VERSION ""

NS_ :

BS_:

BU_: XXX

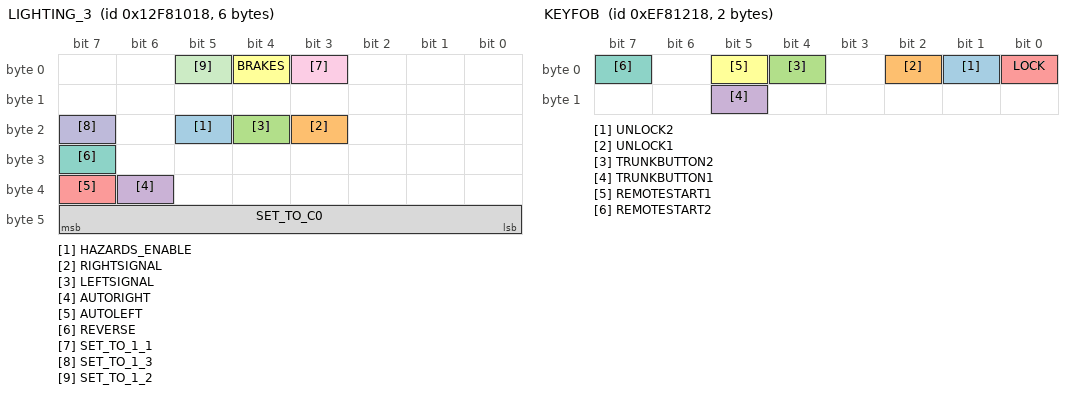
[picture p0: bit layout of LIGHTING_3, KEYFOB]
BO_ 318246936 LIGHTING_3: 6 XXX
 SG_ HAZARDS_ENABLE : 21|1@0+ (1,0) [0|1] "" XXX
 SG_ RIGHTSIGNAL : 19|1@0+ (1,0) [0|1] "" XXX
 SG_ LEFTSIGNAL : 20|1@0+ (1,0) [0|3] "" XXX
 SG_ AUTORIGHT : 38|1@0+ (1,0) [0|1] "" XXX
 SG_ AUTOLEFT : 39|1@0+ (1,0) [0|1] "" XXX
 SG_ BRAKES : 4|1@0+ (1,0) [0|1] "" XXX
 SG_ REVERSE : 31|1@0+ (1,0) [0|1] "" XXX
 SG_ SET_TO_C0 : 47|8@0+ (1,0) [0|255] "" XXX
 SG_ SET_TO_1_1 : 3|1@0+ (1,0) [0|1] "" XXX
 SG_ SET_TO_1_3 : 23|1@0+ (1,0) [0|3] "" XXX
 SG_ SET_TO_1_2 : 5|1@0+ (1,0) [0|3] "" XXX

BO_ 251138584 KEYFOB: 2 XXX
 SG_ UNLOCK2 : 1|1@0+ (1,0) [0|1] "" XXX
 SG_ UNLOCK1 : 2|1@0+ (1,0) [0|1] "" XXX
 SG_ TRUNKBUTTON2 : 4|1@0+ (1,0) [0|1] "" XXX
 SG_ TRUNKBUTTON1 : 13|1@0+ (1,0) [0|1] "" XXX
 SG_ LOCK : 0|1@0+ (1,0) [0|1] "" XXX
 SG_ REMOTESTART1 : 5|1@0+ (1,0) [0|1] "" XXX
 SG_ REMOTESTART2 : 7|1@0+ (1,0) [0|1] "" XXX

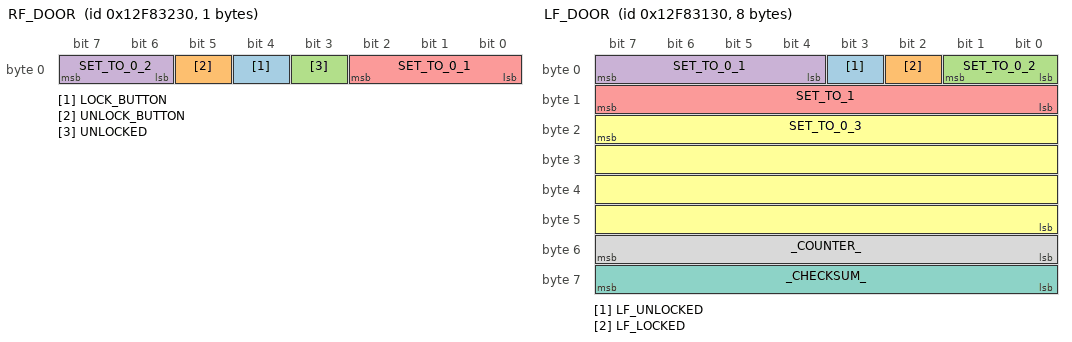
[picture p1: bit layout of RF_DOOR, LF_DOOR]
BO_ 318255664 RF_DOOR: 1 XXX
 SG_ LOCK_BUTTON : 4|1@0+ (1,0) [0|1] "" XXX
 SG_ UNLOCK_BUTTON : 5|1@0+ (1,0) [0|1] "" XXX
 SG_ UNLOCKED : 3|1@0+ (1,0) [0|1] "" XXX
 SG_ SET_TO_0_2 : 7|2@0+ (1,0) [0|3] "" XXX
 SG_ SET_TO_0_1 : 0|3@1+ (1,0) [0|7] "" XXX

BO_ 318255408 LF_DOOR: 8 XXX
 SG_ LF_UNLOCKED : 3|1@0+ (1,0) [0|1] "" XXX
 SG_ LF_LOCKED : 2|1@0+ (1,0) [0|1] "" XXX
 SG_ SET_TO_0_2 : 0|2@1+ (1,0) [0|3] "" XXX
 SG_ SET_TO_0_1 : 7|4@0+ (1,0) [0|15] "" XXX
 SG_ SET_TO_1 : 15|8@0+ (1,0) [0|255] "" XXX
 SG_ SET_TO_0_3 : 23|32@0+ (1,0) [0|4294967295] "" XXX
 SG_ _CHECKSUM_ : 56|8@1+ (1,0) [0|255] "" XXX
 SG_ _COUNTER_ : 48|8@1+ (1,0) [0|255] "" XXX

BO_ 184057368 UNK4: 3 XXX
 SG_ SET_TO_0_1 : 7|8@0+ (1,0) [0|255] "" XXX
 SG_ SET_TO_0_2 : 23|8@0+ (1,0) [0|255] "" XXX
 SG_ SET_TO_X4 : 15|8@0+ (1,0) [0|255] "" XXX

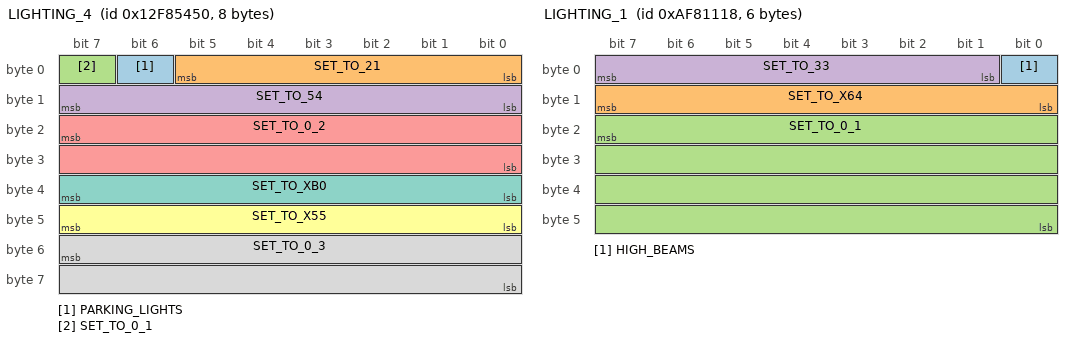
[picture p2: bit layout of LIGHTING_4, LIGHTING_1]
BO_ 318264400 LIGHTING_4: 8 XXX
 SG_ PARKING_LIGHTS : 6|1@0+ (1,0) [0|1] "" XXX
 SG_ SET_TO_21 : 5|6@0+ (1,0) [0|1] "" XXX
 SG_ SET_TO_0_1 : 7|1@0+ (1,0) [0|1] "" XXX
 SG_ SET_TO_54 : 15|8@0+ (1,0) [0|1] "" XXX
 SG_ SET_TO_0_2 : 23|16@0+ (1,0) [0|65535] "" XXX
 SG_ SET_TO_X55 : 47|8@0+ (1,0) [0|255] "" XXX
 SG_ SET_TO_XB0 : 39|8@0+ (1,0) [0|255] "" XXX
 SG_ SET_TO_0_3 : 55|16@0+ (1,0) [0|65535] "" XXX

BO_ 184029464 LIGHTING_1: 6 XXX
 SG_ HIGH_BEAMS : 0|1@0+ (1,0) [0|1] "" XXX
 SG_ SET_TO_X64 : 15|8@0+ (1,0) [0|255] "" XXX
 SG_ SET_TO_0_1 : 23|32@0+ (1,0) [0|4294967295] "" XXX
 SG_ SET_TO_33 : 7|7@0+ (1,0) [0|255] "" XXX

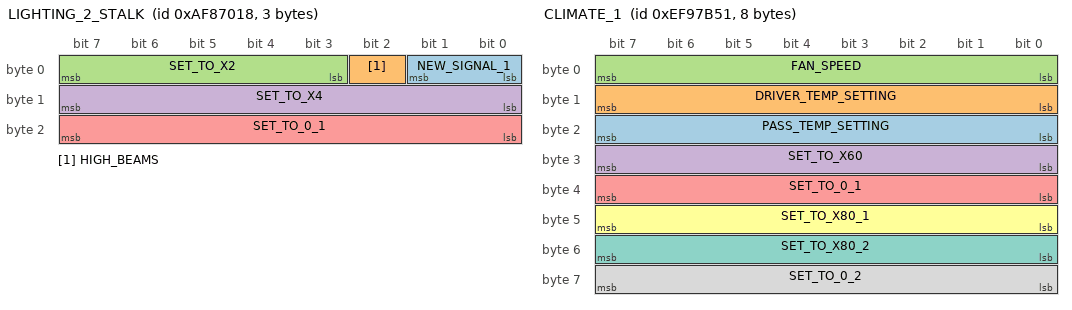
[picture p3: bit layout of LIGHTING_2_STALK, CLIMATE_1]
BO_ 184053784 LIGHTING_2_STALK: 3 XXX
 SG_ NEW_SIGNAL_1 : 0|2@1+ (1,0) [0|3] "" XXX
 SG_ HIGH_BEAMS : 2|1@0+ (1,0) [0|1] "" XXX
 SG_ SET_TO_X2 : 7|5@0+ (1,0) [0|255] "" XXX
 SG_ SET_TO_X4 : 15|8@0+ (1,0) [0|255] "" XXX
 SG_ SET_TO_0_1 : 23|8@0+ (1,0) [0|255] "" XXX

BO_ 318259736 RR_DOOR: 1 XXX
 SG_ UNLOCKED : 7|1@0+ (1,0) [0|1] "" XXX
 SG_ SET_TO_0_1 : 6|7@0+ (1,0) [0|1] "" XXX

BO_ 318288034 HEATED_SEATS: 2 XXX
 SG_ PASS_SEAT : 2|2@0+ (1,0) [0|3] "" XXX
 SG_ DRIVER_SEAT : 6|2@0+ (1,0) [0|3] "" XXX

BO_ 251231057 CLIMATE_1: 8 XXX
 SG_ PASS_TEMP_SETTING : 16|8@1+ (1,0) [0|255] "" XXX
 SG_ DRIVER_TEMP_SETTING : 8|8@1+ (1,0) [0|255] "" XXX
 SG_ FAN_SPEED : 0|8@1+ (1,0) [0|255] "" XXX
 SG_ SET_TO_X60 : 31|8@0+ (1,0) [0|1099511627775] "" XXX
 SG_ SET_TO_0_1 : 39|8@0+ (1,0) [0|255] "" XXX
 SG_ SET_TO_X80_1 : 47|8@0+ (1,0) [0|255] "" XXX
 SG_ SET_TO_X80_2 : 55|8@0+ (1,0) [0|255] "" XXX
 SG_ SET_TO_0_2 : 63|8@0+ (1,0) [0|255] "" XXX

BO_ 251142168 DOOR_LOCKS: 1 XXX
 SG_ LOCKACTION_STATUS : 7|2@0+ (1,0) [0|1] "" XXX
 SG_ SET_TO_0_ : 5|6@0+ (1,0) [0|63] "" XXX

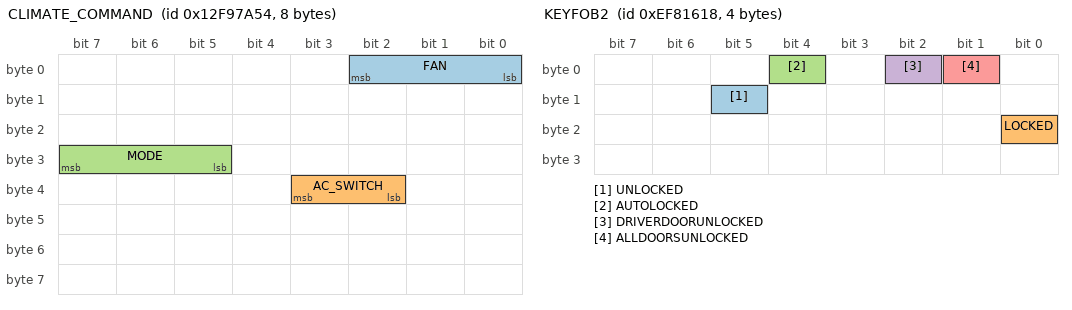
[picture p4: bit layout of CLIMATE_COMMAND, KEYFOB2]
BO_ 318339668 CLIMATE_COMMAND: 8 XXX
 SG_ FAN : 0|3@1+ (1,0) [0|7] "" XXX
 SG_ AC_SWITCH : 34|2@1+ (1,0) [0|3] "" XXX
 SG_ MODE : 31|3@0+ (1,0) [0|7] "" XXX

BO_ 251139608 KEYFOB2: 4 XXX
 SG_ UNLOCKED : 13|1@0+ (1,0) [0|1] "" XXX
 SG_ LOCKED : 16|1@0+ (1,0) [0|1] "" XXX
 SG_ AUTOLOCKED : 4|1@0+ (1,0) [0|1] "" XXX
 SG_ DRIVERDOORUNLOCKED : 2|1@0+ (1,0) [0|1] "" XXX
 SG_ ALLDOORSUNLOCKED : 1|1@0+ (1,0) [0|1] "" XXX

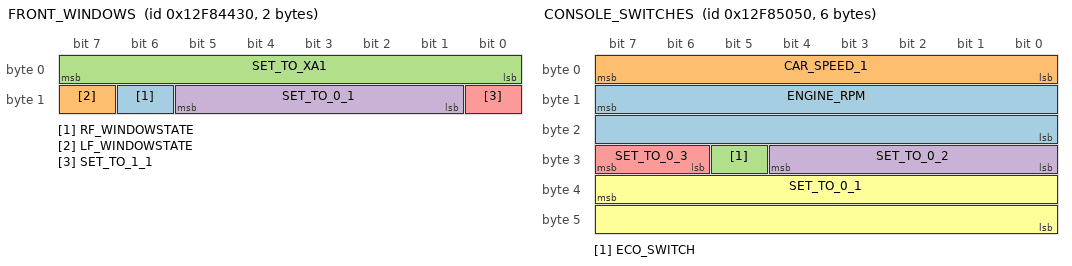
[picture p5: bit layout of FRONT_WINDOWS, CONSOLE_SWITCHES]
BO_ 318260272 FRONT_WINDOWS: 2 XXX
 SG_ RF_WINDOWSTATE : 14|1@0+ (1,0) [0|1] "" XXX
 SG_ LF_WINDOWSTATE : 15|1@0+ (1,0) [0|1] "" XXX
 SG_ SET_TO_XA1 : 7|8@0+ (1,0) [0|255] "" XXX
 SG_ SET_TO_0_1 : 13|5@0+ (1,0) [0|1] "" XXX
 SG_ SET_TO_1_1 : 8|1@0+ (1,0) [0|1] "" XXX

BO_ 318263376 CONSOLE_SWITCHES: 6 XXX
 SG_ ENGINE_RPM : 15|16@0+ (1,0) [0|65535] "" XXX
 SG_ CAR_SPEED_1 : 7|8@0+ (1,0) [0|255] "" XXX
 SG_ ECO_SWITCH : 29|1@0+ (1,0) [0|1] "" XXX
 SG_ SET_TO_0_2 : 28|5@0+ (1,0) [0|31] "" XXX
 SG_ SET_TO_0_3 : 31|2@0+ (1,0) [0|3] "" XXX
 SG_ SET_TO_0_1 : 39|16@0+ (1,0) [0|255] "" XXX

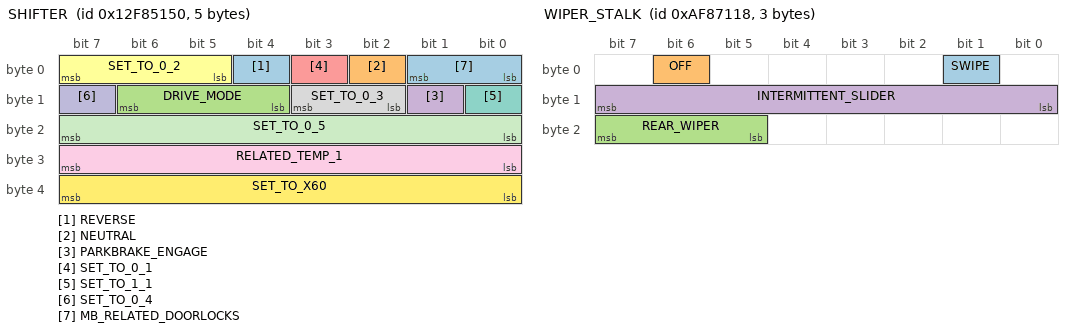
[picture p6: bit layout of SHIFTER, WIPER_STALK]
BO_ 318263632 SHIFTER: 5 XXX
 SG_ REVERSE : 4|1@0+ (1,0) [0|1] "" XXX
 SG_ NEUTRAL : 2|1@0+ (1,0) [0|1] "" XXX
 SG_ DRIVE_MODE : 14|3@0+ (1,0) [0|7] "" XXX
 SG_ PARKBRAKE_ENGAGE : 9|1@0+ (1,0) [0|1] "" XXX
 SG_ SET_TO_0_1 : 3|1@0+ (1,0) [0|1] "" XXX
 SG_ SET_TO_0_2 : 7|3@0+ (1,0) [0|7] "" XXX
 SG_ SET_TO_1_1 : 8|1@0+ (1,0) [0|1] "" XXX
 SG_ SET_TO_0_3 : 10|2@1+ (1,0) [0|3] "" XXX
 SG_ RELATED_TEMP_1 : 31|8@0+ (1,0) [0|255] "" XXX
 SG_ SET_TO_0_4 : 15|1@0+ (1,0) [0|1] "" XXX
 SG_ SET_TO_0_5 : 23|8@0+ (1,0) [0|16777215] "" XXX
 SG_ SET_TO_X60 : 39|8@0+ (1,0) [0|255] "" XXX
 SG_ MB_RELATED_DOORLOCKS : 1|2@0+ (1,0) [0|1] "" XXX

BO_ 318337360 STEERING_1: 3 XXX
 SG_ STEER_ANGLE : 15|16@0- (1,0) [0|255] "" XXX
 SG_ SET_TO_XE0 : 7|8@0+ (1,0) [0|255] "" XXX

BO_ 184054040 WIPER_STALK: 3 XXX
 SG_ SWIPE : 1|1@0+ (1,0) [0|1] "" XXX
 SG_ OFF : 6|1@0+ (1,0) [0|1] "" XXX
 SG_ REAR_WIPER : 23|3@0+ (1,0) [0|7] "" XXX
 SG_ INTERMITTENT_SLIDER : 15|8@0+ (1,0) [0|255] "" XXX

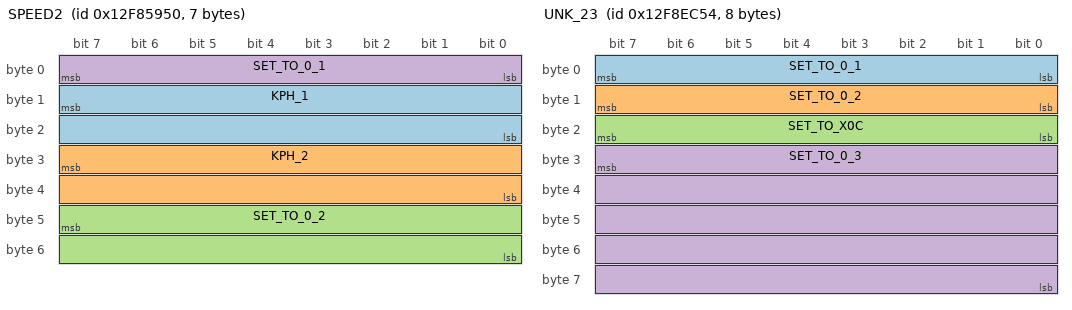
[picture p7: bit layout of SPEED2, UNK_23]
BO_ 318265680 SPEED2: 7 XXX
 SG_ KPH_1 : 15|16@0+ (0.01,0) [0|65535] "" XXX
 SG_ KPH_2 : 31|16@0+ (0.01,0) [0|65535] "" XXX
 SG_ SET_TO_0_2 : 47|16@0+ (1,0) [0|65535] "" XXX
 SG_ SET_TO_0_1 : 7|8@0+ (1,0) [0|255] "" XXX

BO_ 318303316 UNK_23: 8 XXX
 SG_ SET_TO_0_1 : 7|8@0+ (1,0) [0|255] "" XXX
 SG_ SET_TO_0_2 : 15|8@0+ (1,0) [0|255] "" XXX
 SG_ SET_TO_X0C : 23|8@0+ (1,0) [0|255] "" XXX
 SG_ SET_TO_0_3 : 31|40@0+ (1,0) [0|1099511627775] "" XXX

BO_ 318259480 LR_DOOR: 1 XXX
 SG_ UNLOCKED : 7|1@0+ (1,0) [0|1] "" XXX
 SG_ SET_TO_0_1 : 6|7@0+ (1,0) [0|1] "" XXX

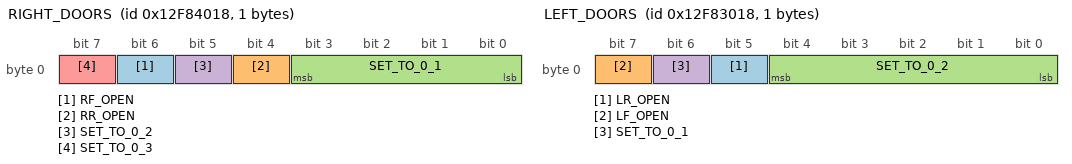
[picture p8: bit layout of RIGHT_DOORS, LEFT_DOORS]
BO_ 318259224 RIGHT_DOORS: 1 XXX
 SG_ RF_OPEN : 6|1@0+ (1,0) [0|1] "" XXX
 SG_ RR_OPEN : 4|1@0+ (1,0) [0|1] "" XXX
 SG_ SET_TO_0_1 : 3|4@0+ (1,0) [0|1] "" XXX
 SG_ SET_TO_0_2 : 5|1@0+ (1,0) [0|1] "" XXX
 SG_ SET_TO_0_3 : 7|1@0+ (1,0) [0|1] "" XXX

BO_ 318255128 LEFT_DOORS: 1 XXX
 SG_ LR_OPEN : 5|1@0+ (1,0) [0|1] "" XXX
 SG_ LF_OPEN : 7|1@0+ (1,0) [0|1] "" XXX
 SG_ SET_TO_0_2 : 4|5@0+ (1,0) [0|31] "" XXX
 SG_ SET_TO_0_1 : 6|1@0+ (1,0) [0|1] "" XXX

BO_ 318275608 TRUNK_1: 1 XXX
 SG_ RELEASE_BUTTON : 7|1@0+ (1,0) [0|1] "" XXX
 SG_ SET_TO_0_1 : 6|7@0+ (1,0) [0|127] "" XXX

BO_ 318259992 TRUNK_2: 1 XXX
 SG_ TRUNK_OPEN : 7|1@0+ (1,0) [0|1] "" XXX
 SG_ SET_TO_0_1 : 6|7@0+ (1,0) [0|1] "" XXX

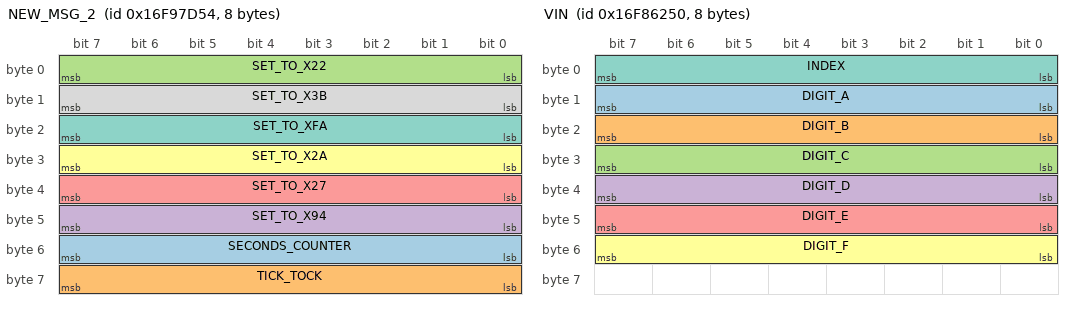
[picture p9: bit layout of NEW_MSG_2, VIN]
BO_ 385449300 NEW_MSG_2: 8 XXX
 SG_ SECONDS_COUNTER : 55|8@0+ (1,0) [0|255] "" XXX
 SG_ TICK_TOCK : 56|8@1+ (1,0) [0|255] "" XXX
 SG_ SET_TO_X22 : 7|8@0+ (1,0) [0|65535] "" XXX
 SG_ SET_TO_X94 : 47|8@0+ (1,0) [0|255] "" XXX
 SG_ SET_TO_X27 : 39|8@0+ (1,0) [0|1] "" XXX
 SG_ SET_TO_X2A : 31|8@0+ (1,0) [0|255] "" XXX
 SG_ SET_TO_XFA : 23|8@0+ (1,0) [0|1] "" XXX
 SG_ SET_TO_X3B : 15|8@0+ (1,0) [0|255] "" XXX

BO_ 385376848 VIN: 8 XXX
 SG_ DIGIT_A : 15|8@0+ (1,0) [0|255] "" XXX
 SG_ DIGIT_B : 23|8@0+ (1,0) [0|255] "" XXX
 SG_ DIGIT_C : 31|8@0+ (1,0) [0|255] "" XXX
 SG_ DIGIT_D : 39|8@0+ (1,0) [0|255] "" XXX
 SG_ DIGIT_E : 47|8@0+ (1,0) [0|255] "" XXX
 SG_ DIGIT_F : 55|8@0+ (1,0) [0|255] "" XXX
 SG_ INDEX : 7|8@0+ (1,0) [0|255] "" XXX

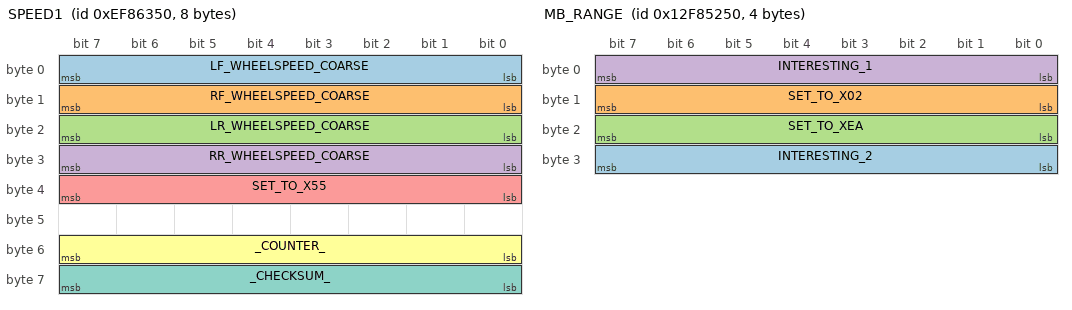
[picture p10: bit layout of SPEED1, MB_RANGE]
BO_ 251159376 SPEED1: 8 XXX
 SG_ LF_WHEELSPEED_COARSE : 0|8@1+ (1,0) [0|255] "" XXX
 SG_ RF_WHEELSPEED_COARSE : 8|8@1+ (1,0) [0|255] "" XXX
 SG_ LR_WHEELSPEED_COARSE : 16|8@1+ (1,0) [0|255] "" XXX
 SG_ RR_WHEELSPEED_COARSE : 24|8@1+ (1,0) [0|255] "" XXX
 SG_ SET_TO_X55 : 39|8@0+ (1,0) [0|255] "" XXX
 SG_ _COUNTER_ : 55|8@0+ (1,0) [0|255] "" XXX
 SG_ _CHECKSUM_ : 63|8@0+ (1,0) [0|255] "" XXX

BO_ 251234897 VEH_DYN_1: 2 XXX
 SG_ unk_maybe_fuel_usage : 7|16@0- (1,0) [0|255] "" XXX

BO_ 318338128 STEERING_2: 2 XXX
 SG_ RELATED_STEER_ANGLE : 7|8@0+ (1,0) [0|255] "" XXX
 SG_ MAYBE_STEER_DIRECTION : 15|8@0+ (1,0) [0|255] "" XXX

BO_ 318292308 NEW_MSG_5: 8 XXX
 SG_ NEW_SIGNAL_1 : 7|24@0+ (1,0) [0|65535] "" XXX
 SG_ NEW_SIGNAL_3 : 31|24@0+ (1,0) [0|65535] "" XXX
 SG_ NEW_SIGNAL_4 : 55|16@0+ (1,0) [0|65535] "" XXX

BO_ 318263888 MB_RANGE: 4 XXX
 SG_ INTERESTING_2 : 31|8@0+ (1,0) [0|255] "" XXX
 SG_ SET_TO_X02 : 15|8@0+ (1,0) [0|255] "" XXX
 SG_ SET_TO_XEA : 23|8@0+ (1,0) [0|255] "" XXX
 SG_ INTERESTING_1 : 7|8@0+ (1,0) [0|255] "" XXX

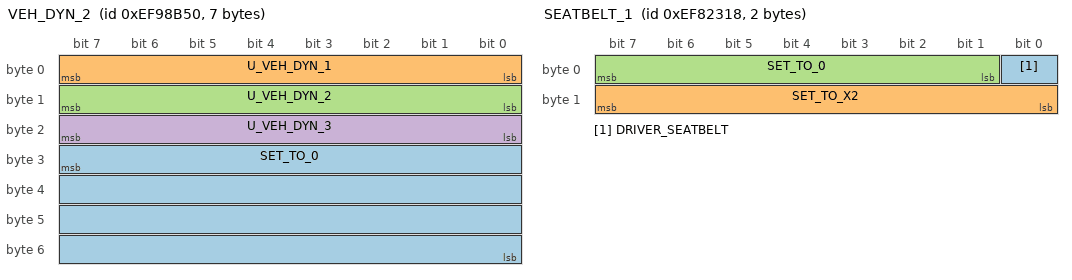
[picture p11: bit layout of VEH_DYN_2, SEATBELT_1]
BO_ 251235152 VEH_DYN_2: 7 XXX
 SG_ SET_TO_0 : 31|32@0+ (1,0) [0|4294967295] "" XXX
 SG_ U_VEH_DYN_1 : 7|8@0+ (1,0) [0|255] "" XXX
 SG_ U_VEH_DYN_2 : 15|8@0+ (1,0) [0|255] "" XXX
 SG_ U_VEH_DYN_3 : 23|8@0+ (1,0) [0|255] "" XXX

BO_ 318333008 UNK_1: 7 XXX
 SG_ SET_TO_0_1 : 7|32@0+ (1,0) [0|255] "" XXX
 SG_ SET_TO_0_X09 : 47|8@0+ (1,0) [0|255] "" XXX
 SG_ SET_TO_0_X40 : 39|8@0+ (1,0) [0|255] "" XXX
 SG_ SET_TO_0_2 : 55|8@0+ (1,0) [0|255] "" XXX

BO_ 318343249 UNK_2: 3 XXX
 SG_ SET_TO_X40 : 7|8@0+ (1,0) [0|255] "" XXX
 SG_ SET_TO_0_1 : 15|8@0+ (1,0) [0|255] "" XXX
 SG_ SET_TO_0_2 : 23|8@0+ (1,0) [0|255] "" XXX

BO_ 184057168 UNK_3: 2 XXX
 SG_ SET_TO_0_1 : 7|8@0+ (1,0) [0|255] "" XXX
 SG_ SET_TO_0_2 : 15|8@0+ (1,0) [0|255] "" XXX

BO_ 184121680 UNK_5: 1 XXX
 SG_ SET_TO_0 : 7|8@0+ (1,0) [0|255] "" XXX

BO_ 251139096 UNK_6: 1 XXX
 SG_ SET_TO_0 : 7|8@0+ (1,0) [0|255] "" XXX

BO_ 251139352 UNK_7: 1 XXX
 SG_ SET_TO_2 : 7|8@0+ (1,0) [0|255] "" XXX

BO_ 251142936 SEATBELT_1: 2 XXX
 SG_ DRIVER_SEATBELT : 0|1@0+ (1,0) [0|1] "" XXX
 SG_ SET_TO_X2 : 15|8@0+ (1,0) [0|255] "" XXX
 SG_ SET_TO_0 : 7|7@0+ (1,0) [0|255] "" XXX

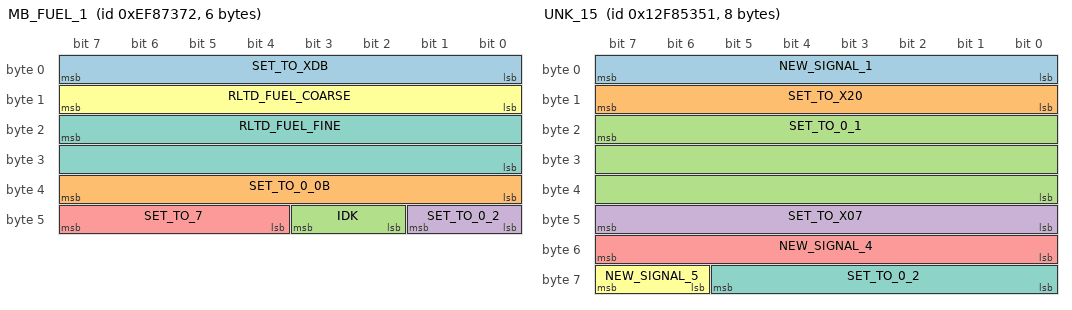
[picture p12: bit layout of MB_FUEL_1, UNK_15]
BO_ 251163506 MB_FUEL_1: 6 XXX
 SG_ SET_TO_XDB : 7|8@0+ (1,0) [0|255] "" XXX
 SG_ SET_TO_0_0B : 39|8@0+ (1,0) [0|255] "" XXX
 SG_ IDK : 42|2@1+ (1,0) [0|3] "" XXX
 SG_ SET_TO_0_2 : 40|2@1+ (1,0) [0|3] "" XXX
 SG_ SET_TO_7 : 47|4@0+ (1,0) [0|255] "" XXX
 SG_ RLTD_FUEL_COARSE : 15|8@0+ (1,0) [0|255] "" XXX
 SG_ RLTD_FUEL_FINE : 23|16@0+ (1,0) [0|1] "" XXX

BO_ 251167000 UNK_9: 1 XXX
 SG_ SET_TO_0 : 7|8@0+ (1,0) [0|255] "" XXX

BO_ 251167512 UNK_10: 8 XXX
 SG_ SET_TO_0_1 : 7|24@0+ (1,0) [0|8388607] "" XXX
 SG_ SET_TO_X09 : 31|8@0+ (1,0) [0|255] "" XXX
 SG_ SET_TO_0_2 : 39|32@0+ (1,0) [0|4294967295] "" XXX

BO_ 251171864 UNK_11: 3 XXX
 SG_ NEW_SIGNAL_1 : 7|8@0+ (1,0) [0|255] "" XXX
 SG_ NEW_SIGNAL_2 : 15|8@0+ (1,0) [0|255] "" XXX
 SG_ NEW_SIGNAL_3 : 23|8@0+ (1,0) [0|255] "" XXX

BO_ 318254104 UNK_12: 1 XXX
 SG_ SET_TO_X20 : 7|8@0+ (1,0) [0|255] "" XXX

BO_ 318256152 UNK_13: 1 XXX
 SG_ SET_TO_X20 : 7|8@0+ (1,0) [0|255] "" XXX

BO_ 318261784 UNK_14: 1 XXX
 SG_ SET_TO_0_1 : 7|8@0+ (1,0) [0|255] "" XXX

BO_ 318264145 UNK_15: 8 XXX
 SG_ NEW_SIGNAL_1 : 7|8@0+ (1,0) [0|65535] "" XXX
 SG_ SET_TO_X20 : 15|8@0+ (1,0) [0|1] "" XXX
 SG_ SET_TO_0_1 : 23|24@0+ (1,0) [0|1] "" XXX
 SG_ SET_TO_X07 : 47|8@0+ (1,0) [0|1] "" XXX
 SG_ NEW_SIGNAL_4 : 55|8@0+ (1,0) [0|1] "" XXX
 SG_ NEW_SIGNAL_5 : 62|2@1+ (1,0) [0|1] "" XXX
 SG_ SET_TO_0_2 : 61|6@0+ (1,0) [0|63] "" XXX

BO_ 318266448 UNK_16: 6 XXX
 SG_ SET_TO_0_1 : 7|48@0+ (1,0) [0|255] "" XXX

BO_ 318267728 UNK_17: 8 XXX
 SG_ SET_TO_0_1 : 7|24@0+ (1,0) [0|1] "" XXX
 SG_ SET_TO_X40 : 31|8@0+ (1,0) [0|255] "" XXX
 SG_ SET_TO_0_2 : 39|32@0+ (1,0) [0|1] "" XXX

BO_ 318273560 UNK_18: 1 XXX
 SG_ SET_TO_0_1 : 7|8@0+ (1,0) [0|255] "" XXX

BO_ 318279704 UNK_19: 4 XXX
 SG_ SET_TO_0_1 : 7|8@0+ (1,0) [0|255] "" XXX
 SG_ SET_TO_X01 : 15|8@0+ (1,0) [0|255] "" XXX
 SG_ SET_TO_0_2 : 23|8@0+ (1,0) [0|255] "" XXX
 SG_ SET_TO_0_3 : 31|8@0+ (1,0) [0|255] "" XXX

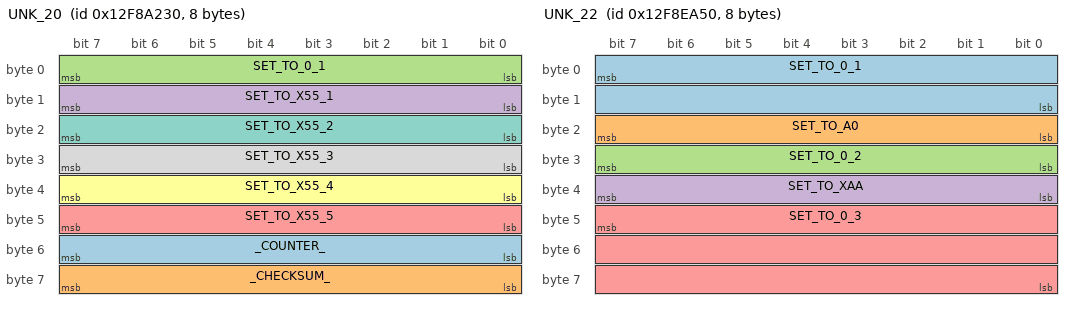
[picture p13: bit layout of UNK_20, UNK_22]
BO_ 318284336 UNK_20: 8 XXX
 SG_ _COUNTER_ : 55|8@0+ (1,0) [0|255] "" XXX
 SG_ _CHECKSUM_ : 63|8@0+ (1,0) [0|1] "" XXX
 SG_ SET_TO_0_1 : 7|8@0+ (1,0) [0|255] "" XXX
 SG_ SET_TO_X55_1 : 15|8@0+ (1,0) [0|255] "" XXX
 SG_ SET_TO_X55_5 : 47|8@0+ (1,0) [0|255] "" XXX
 SG_ SET_TO_X55_4 : 39|8@0+ (1,0) [0|255] "" XXX
 SG_ SET_TO_X55_2 : 23|8@0+ (1,0) [0|255] "" XXX
 SG_ SET_TO_X55_3 : 31|8@0+ (1,0) [0|255] "" XXX

BO_ 318288209 UNK_21: 4 XXX
 SG_ SET_TO_0_1 : 7|32@0+ (1,0) [0|4294967295] "" XXX

BO_ 318302800 UNK_22: 8 XXX
 SG_ SET_TO_0_1 : 7|16@0+ (1,0) [0|65535] "" XXX
 SG_ SET_TO_A0 : 23|8@0+ (1,0) [0|255] "" XXX
 SG_ SET_TO_0_2 : 31|8@0+ (1,0) [0|255] "" XXX
 SG_ SET_TO_XAA : 39|8@0+ (1,0) [0|255] "" XXX
 SG_ SET_TO_0_3 : 47|24@0+ (1,0) [0|16777215] "" XXX

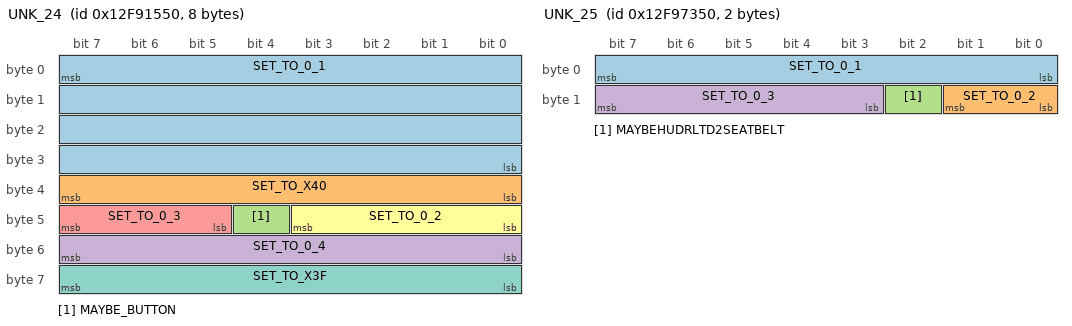
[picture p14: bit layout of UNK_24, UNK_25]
BO_ 318313808 UNK_24: 8 XXX
 SG_ SET_TO_0_1 : 7|32@0+ (1,0) [0|4294967295] "" XXX
 SG_ SET_TO_X40 : 39|8@0+ (1,0) [0|255] "" XXX
 SG_ MAYBE_BUTTON : 44|1@0+ (1,0) [0|1] "" XXX
 SG_ SET_TO_0_4 : 55|8@0+ (1,0) [0|255] "" XXX
 SG_ SET_TO_0_3 : 47|3@0+ (1,0) [0|65535] "" XXX
 SG_ SET_TO_0_2 : 40|4@1+ (1,0) [0|15] "" XXX
 SG_ SET_TO_X3F : 63|8@0+ (1,0) [0|255] "" XXX

BO_ 318337872 UNK_25: 2 XXX
 SG_ SET_TO_0_1 : 7|8@0+ (1,0) [0|255] "" XXX
 SG_ SET_TO_0_2 : 9|2@0+ (1,0) [0|1] "" XXX
 SG_ MAYBEHUDRLTD2SEATBELT : 10|1@0+ (1,0) [0|1] "" XXX
 SG_ SET_TO_0_3 : 15|5@0+ (1,0) [0|255] "" XXX

BO_ 318361624 UNK_26: 1 XXX
 SG_ SET_TO_0_1 : 7|8@0+ (1,0) [0|255] "" XXX

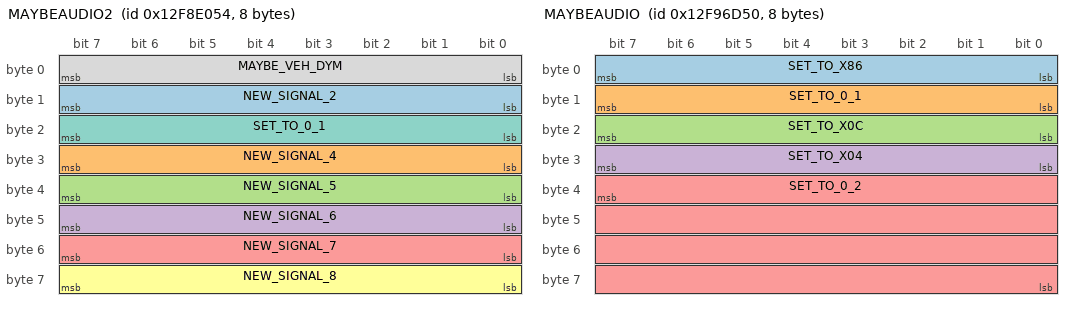
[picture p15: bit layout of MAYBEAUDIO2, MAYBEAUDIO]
BO_ 318300244 MAYBEAUDIO2: 8 XXX
 SG_ NEW_SIGNAL_2 : 15|8@0+ (1,0) [0|255] "" XXX
 SG_ NEW_SIGNAL_4 : 31|8@0+ (1,0) [0|255] "" XXX
 SG_ NEW_SIGNAL_5 : 39|8@0+ (1,0) [0|255] "" XXX
 SG_ NEW_SIGNAL_6 : 47|8@0+ (1,0) [0|255] "" XXX
 SG_ NEW_SIGNAL_7 : 55|8@0+ (1,0) [0|255] "" XXX
 SG_ NEW_SIGNAL_8 : 63|8@0+ (1,0) [0|255] "" XXX
 SG_ SET_TO_0_1 : 23|8@0+ (1,0) [0|255] "" XXX
 SG_ MAYBE_VEH_DYM : 7|8@0+ (1,0) [0|255] "" XXX

BO_ 318336336 MAYBEAUDIO: 8 XXX
 SG_ SET_TO_X86 : 7|8@0+ (1,0) [0|255] "" XXX
 SG_ SET_TO_0_1 : 15|8@0+ (1,0) [0|255] "" XXX
 SG_ SET_TO_X0C : 23|8@0+ (1,0) [0|255] "" XXX
 SG_ SET_TO_X04 : 31|8@0+ (1,0) [0|255] "" XXX
 SG_ SET_TO_0_2 : 39|32@0+ (1,0) [0|4294967295] "" XXX

BO_ 318251544 UNK_27: 1 XXX
 SG_ SET_TO_X80 : 7|8@0+ (1,0) [0|255] "" XXX

BO_ 318332752 MB_SECURITY_2: 8 XXX

BO_ 318336596 MB_SECURITY_3: 8 XXX

BO_ 318340176 MB_SECURITY_4: 1 XXX

BO_ 317390673 MB_SECURITY_5: 2 XXX

BO_ 317390676 MB_SECURITY_6: 8 XXX

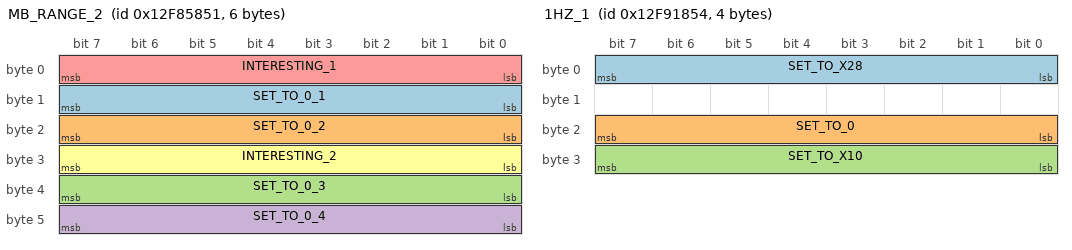
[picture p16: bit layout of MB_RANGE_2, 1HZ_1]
BO_ 318265425 MB_RANGE_2: 6 XXX
 SG_ SET_TO_0_1 : 15|8@0+ (1,0) [0|255] "" XXX
 SG_ SET_TO_0_2 : 23|8@0+ (1,0) [0|255] "" XXX
 SG_ SET_TO_0_3 : 39|8@0+ (1,0) [0|255] "" XXX
 SG_ SET_TO_0_4 : 47|8@0+ (1,0) [0|255] "" XXX
 SG_ INTERESTING_1 : 7|8@0+ (1,0) [0|255] "" XXX
 SG_ INTERESTING_2 : 31|8@0+ (1,0) [0|255] "" XXX

BO_ 318302292 UNK_EVENT_1: 4 XXX

BO_ 318302548 UNK_EVENT_2: 8 XXX

BO_ 318314580 1HZ_1: 4 XXX
 SG_ SET_TO_X28 : 7|8@0+ (1,0) [0|255] "" XXX
 SG_ SET_TO_0 : 23|8@0+ (1,0) [0|255] "" XXX
 SG_ SET_TO_X10 : 31|8@0+ (1,0) [0|255] "" XXX

BO_ 318329172 1HZ_2: 8 XXX

BO_ 318333264 3SEC_1: 7 XXX

BO_ 318333520 UNK_EVENT_3: 8 XXX

BO_ 318334800 UNK_EVENT_4: 8 XXX

BO_ 318335824 UNK_EVENT_5: 8 XXX

BO_ 318338640 1HZ_3: 8 XXX

BO_ 318357584 1HZ_4: 8 XXX

BO_ 318357840 1HZ_5: 8 XXX

BO_ 384913492 ACC_EVENT_1: 2 XXX
 SG_ NEW_SIGNAL_1 : 7|8@0+ (1,0) [0|255] "" XXX
 SG_ NEW_SIGNAL_2 : 15|8@0+ (1,0) [0|255] "" XXX

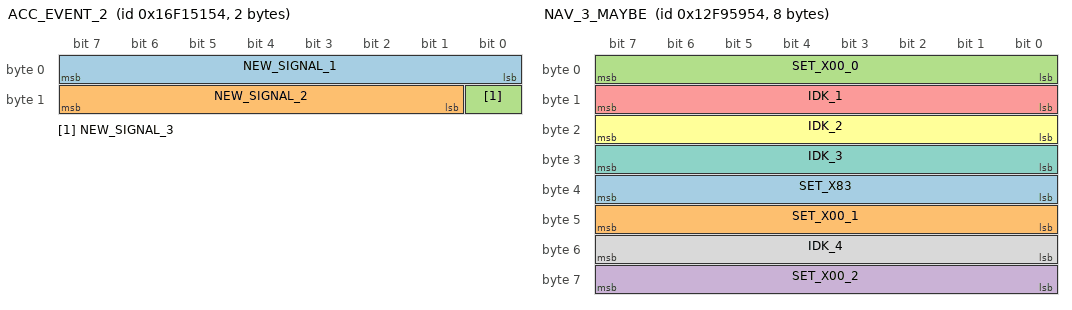
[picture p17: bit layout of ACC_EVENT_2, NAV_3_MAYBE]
BO_ 384913748 ACC_EVENT_2: 2 XXX
 SG_ NEW_SIGNAL_1 : 7|8@0+ (1,0) [0|255] "" XXX
 SG_ NEW_SIGNAL_2 : 15|7@0+ (1,0) [0|127] "" XXX
 SG_ NEW_SIGNAL_3 : 8|1@0+ (1,0) [0|1] "" XXX

BO_ 384914513 ACC_EVENT_4: 8 XXX

BO_ 384914512 ACC_EVENT_3: 8 XXX

BO_ 384914546 30SEC_1: 8 XXX

BO_ 384914594 30SEC_2: 8 XXX

BO_ 384922196 30SEC_3: 2 XXX

BO_ 384934484 30SEC_4: 2 XXX

BO_ 384954392 UNK_EVENT_6: 8 XXX

BO_ 384979992 UNK_EVENT_7: 2 XXX

BO_ 384980016 UNK_EVENT_8: 2 XXX

BO_ 384980048 UNK_EVENT_9: 2 XXX

BO_ 384980049 UNK_EVENT_10: 2 XXX

BO_ 384980082 UNK_EVENT_11: 2 XXX

BO_ 384980130 UNK_EVENT_12: 2 XXX

BO_ 385450324 NEW_MSG_1: 8 XXX
 SG_ SET_TO_X58 : 7|8@0+ (1,0) [0|255] "" XXX

BO_ 251143448 NEW_MSG_3: 8 XXX
 SG_ SET_TO_X14 : 7|8@0+ (1,0) [0|255] "" XXX

BO_ 251174936 NEW_MSG_4: 8 XXX
 SG_ SET_TO_X14 : 7|8@0+ (1,0) [0|255] "" XXX

BO_ 505610008 NEW_MSG_6: 8 XXX
 SG_ SET_TO_X18 : 7|8@0+ (1,0) [0|255] "" XXX
 SG_ SET_TO_0_1 : 15|8@0+ (1,0) [0|255] "" XXX

BO_ 505610064 NEW_MSG_7: 8 XXX
 SG_ SET_TO_X50 : 7|8@0+ (1,0) [0|255] "" XXX
 SG_ SET_TO_0_1 : 15|8@0+ (1,0) [0|255] "" XXX

BO_ 251234129 NEW_MSG_8: 8 XXX
 SG_ SET_TO_0_1 : 7|24@0+ (1,0) [0|255] "" XXX

BO_ 318331220 NAV_3_MAYBE: 8 XXX
 SG_ SET_X83 : 39|8@0+ (1,0) [0|255] "" XXX
 SG_ SET_X00_1 : 47|8@0+ (1,0) [0|255] "" XXX
 SG_ SET_X00_0 : 7|8@0+ (1,0) [0|255] "" XXX
 SG_ SET_X00_2 : 63|8@0+ (1,0) [0|255] "" XXX
 SG_ IDK_1 : 8|8@1+ (1,0) [0|255] "" XXX
 SG_ IDK_2 : 23|8@0+ (1,0) [0|255] "" XXX
 SG_ IDK_3 : 31|8@0+ (1,0) [0|255] "" XXX
 SG_ IDK_4 : 55|8@0+ (1,0) [0|255] "" XXX

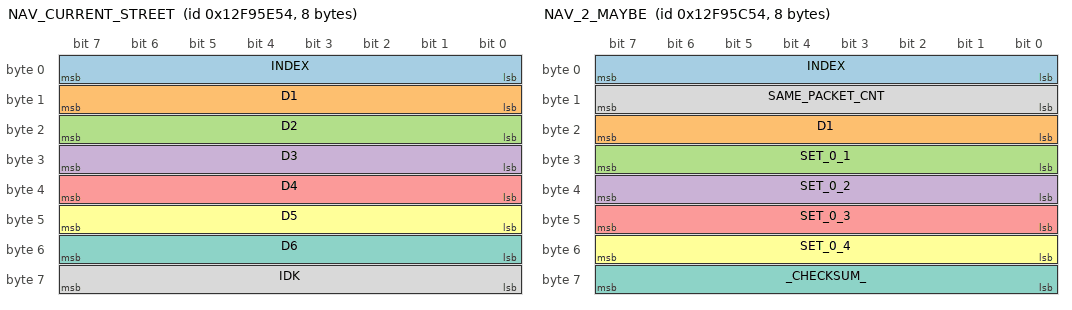
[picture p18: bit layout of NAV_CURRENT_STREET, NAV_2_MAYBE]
BO_ 318332500 NAV_CURRENT_STREET: 8 XXX
 SG_ INDEX : 7|8@0+ (1,0) [0|255] "" XXX
 SG_ D1 : 8|8@1+ (1,0) [0|255] "" XXX
 SG_ D2 : 16|8@1+ (1,0) [0|255] "" XXX
 SG_ D3 : 24|8@1+ (1,0) [0|255] "" XXX
 SG_ D4 : 32|8@1+ (1,0) [0|255] "" XXX
 SG_ D5 : 40|8@1+ (1,0) [0|255] "" XXX
 SG_ D6 : 48|8@1+ (1,0) [0|255] "" XXX
 SG_ IDK : 56|8@1+ (1,0) [0|255] "" XXX

BO_ 318331988 NAV_2_MAYBE: 8 XXX
 SG_ INDEX : 0|8@1+ (1,0) [0|255] "" XXX
 SG_ D1 : 23|8@0+ (1,0) [0|255] "" XXX
 SG_ SET_0_1 : 31|8@0+ (1,0) [0|255] "" XXX
 SG_ SET_0_2 : 39|8@0+ (1,0) [0|255] "" XXX
 SG_ SET_0_3 : 47|8@0+ (1,0) [0|255] "" XXX
 SG_ SET_0_4 : 55|8@0+ (1,0) [0|255] "" XXX
 SG_ _CHECKSUM_ : 63|8@0+ (1,0) [0|255] "" XXX
 SG_ SAME_PACKET_CNT : 15|8@0+ (1,0) [0|255] "" XXX

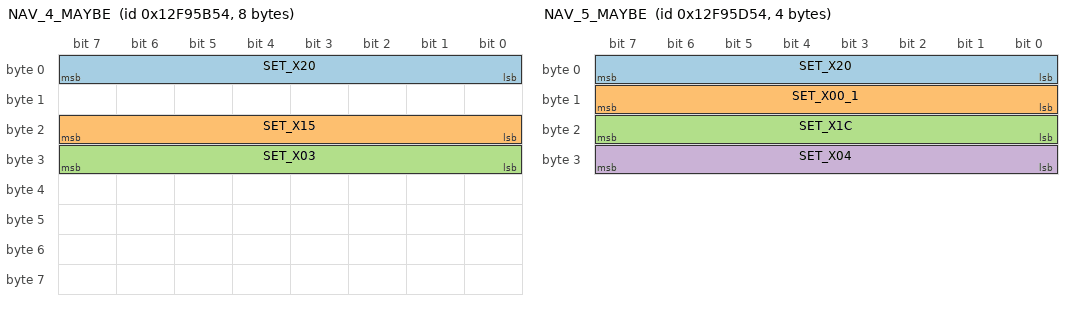
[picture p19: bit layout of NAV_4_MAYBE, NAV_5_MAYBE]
BO_ 318331732 NAV_4_MAYBE: 8 XXX
 SG_ SET_X20 : 7|8@0+ (1,0) [0|255] "" XXX
 SG_ SET_X15 : 23|8@0+ (1,0) [0|255] "" XXX
 SG_ SET_X03 : 31|8@0+ (1,0) [0|255] "" XXX

BO_ 318332244 NAV_5_MAYBE: 4 XXX
 SG_ SET_X20 : 7|8@0+ (1,0) [0|255] "" XXX
 SG_ SET_X00_1 : 15|8@0+ (1,0) [0|255] "" XXX
 SG_ SET_X1C : 23|8@0+ (1,0) [0|255] "" XXX
 SG_ SET_X04 : 31|8@0+ (1,0) [0|255] "" XXX

BO_ 384914456 NAV_6_30SEC: 8 XXX

BO_ 384899156 nav_7_30sec: 2 XXX

CM_ SG_ 318264400 PARKING_LIGHTS "0 = OFF, 1 = ON";
CM_ SG_ 318288034 PASS_SEAT "0 = OFF, 1 = HIGH, 2 = MED, 3 = LO";
CM_ SG_ 318288034 DRIVER_SEAT "0 = OFF, 1 = HIGH, 2 = MED, 3 = LO";
CM_ SG_ 251231057 PASS_TEMP_SETTING "04 = HIGH, 08 = LO";
CM_ SG_ 251231057 DRIVER_TEMP_SETTING "04 = HIGH, 08 = LO";
CM_ SG_ 251231057 FAN_SPEED "en = current n setting, 6n = going to n setting";
CM_ SG_ 251142168 LOCKACTION_STATUS "0 = IDLE, 1 = UNLOCKING, 2 = LOCKING";
CM_ SG_ 318339668 MODE "5 = FACE, 4 = MIX, 3 = FLOOR, 2 = FLOOR_DEFROST";
CM_ SG_ 318260272 RF_WINDOWSTATE "1 = CLOSED, 0 = OPEN";
CM_ SG_ 318260272 LF_WINDOWSTATE "1 = CLOSED, 0 = OPEN";
CM_ SG_ 318263632 DRIVE_MODE "0 = DRIVE, 4 = S, 1 = L";
CM_ SG_ 184054040 REAR_WIPER "0 = OFF, 4 = INT, 1 = ON";
CM_ SG_ 318331988 SAME_PACKET_CNT "0-3";
